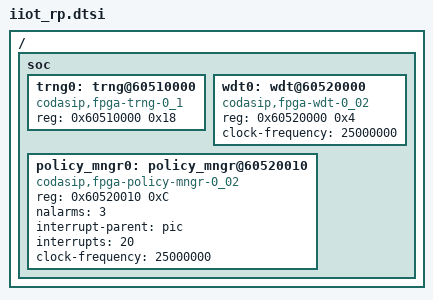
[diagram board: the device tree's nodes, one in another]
/*
 * Copyright (c) 2023 Codasip s.r.o.
 *
 * SPDX-License-Identifier: Apache-2.0
 */

/* See: https://docs.zephyrproject.org/latest/hardware/porting/board_porting.html */

/* Codasip IIOT-RP (Reference Platform) Platform (use with L31 Fluorine Core) */

#include <codasip/inferno.dtsi>

/ {
        soc {
                trng0: trng@60510000 {
                        compatible = "codasip,fpga-trng-0_1";
                        reg = <0x60510000 0x18>;
                        #address-cells = <1>;
                        #size-cells = <0>;
                        status = "okay";
                };
                wdt0: wdt@60520000 {
                        compatible = "codasip,fpga-wdt-0_02";
                        reg = <0x60520000 0x4>;
                        clock-frequency = <25000000>;
                        status = "okay";
                };
                policy_mngr0: policy_mngr@60520010 {
                        compatible = "codasip,fpga-policy-mngr-0_02";
                        reg = <0x60520010 0xC>;
                        nalarms = <3>;
                        interrupt-parent = <&pic>;
                        interrupts = <20>;      /* <20> is irq=5387 (0x150B) returned by DT_IRQ_BY_IDX(DT_NODELABEL(policy_mngr0), 0, irq), 
                                                   which is correct -> 0x1500 is the 20th IRQ (i.e. 20 [+ 1]) 2ND_LEVEL_INTERRUPTS,
                                                   while 0xB is 1st level interrupt &intc 11 */
                        clock-frequency = <25000000>;
                        status = "okay";
                };
        };
};
